# ATmega1281 device description
Architecture: AVR8; Family: megaAVR
Registers are 8-bit, access not given, no defined reset value unless marked. A register's access mark holds for its fields unless they carry their own. Offsets are from the block's base; [hi:lo] are bit positions; {n}, {i} and the like mark numbered series; 'fields as' and 'values as' point back to an identical list.

## EEPROM
Instances: EEPROM 0x00
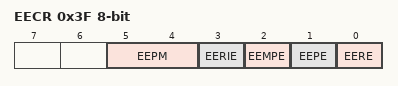
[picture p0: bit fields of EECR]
0x3F EECR — EEPROM Control Register
  [5:4] EEPM — EEPROM Programming Mode Bits
    0=ERASE_AND_WRITE_IN_ONE_OPERATION; 1=ERASE_ONLY; 2=WRITE_ONLY
  [3] EERIE — EEPROM Ready Interrupt Enable
  [2] EEMPE — EEPROM Master Write Enable
  [1] EEPE — EEPROM Write Enable
  [0] EERE — EEPROM Read Enable
0x40 EEDR — EEPROM Data Register
0x41 EEAR 16-bit bits used 11:0 — EEPROM Address Register Low Bytes

## JTAG — JTAG Interface
Instances: JTAG 0x00
0x51 OCDR — On-Chip Debug Related Register in I/O Memory
0x54 MCUSR — MCU Status Register
  [4] JTRF — JTAG Reset Flag
0x55 MCUCR — MCU Control Register
  [7] JTD — JTAG Interface Disable

## EXINT — External Interrupts
Instances: EXINT 0x00
0x3B PCIFR — Pin Change Interrupt Flag Register
  [2:0] PCIF — Pin Change Interrupt Flags
0x3C EIFR — External Interrupt Flag Register
  [7:0] INTF — External Interrupt Flags
0x3D EIMSK — External Interrupt Mask Register
  [7:0] INT — External Interrupt Request 7 Enable
0x68 PCICR — Pin Change Interrupt Control Register
  [2:0] PCIE — Pin Change Interrupt Enables
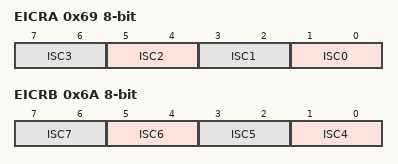
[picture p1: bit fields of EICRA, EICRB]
0x69 EICRA — External Interrupt Control Register A
  [all] fields
    0=LOW_LEVEL_OF_INTX; 1=ANY_LOGICAL_CHANGE_OF_INTX; 2=FALLING_EDGE_OF_INTX; 3=RISING_EDGE_OF_INTX
  [2n+1:2n] ISC{n} (n=0..3) — External Interrupt Sense Control Bit
0x6A EICRB — External Interrupt Control Register B
  [all] fields
    values as the fields of EICRA
  [2n-7:2n-8] ISC{n} (n=4..7) — External Interrupt 7-4 Sense Control Bit
0x6B PCMSK0 — Pin Change Mask Register 0
  [7:0] PCINT — Pin Change Enable mask
0x6C PCMSK1 — Pin Change Mask Register 1
  [7:0] PCINT (bit 8 of the value upward) — Pin Change Enable mask
0x6D PCMSK2 — Pin Change Mask Register 2
  [7:0] PCINT (bit 16 of the value upward) — Pin Change Enable mask

## ADC — Analog-to-Digital Converter
Instances: ADC 0x00
0x78 ADC 16-bit — ADC Data Register Bytes
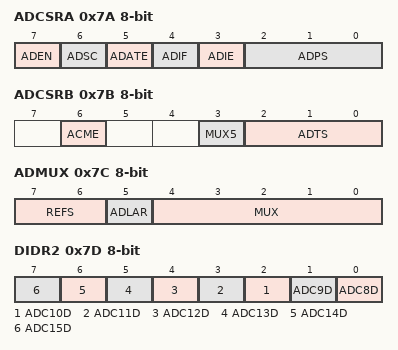
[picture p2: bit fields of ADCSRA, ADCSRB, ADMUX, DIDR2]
0x7A ADCSRA — The ADC Control and Status register A
  [7] ADEN — ADC Enable
  [6] ADSC — ADC Start Conversion
  [5] ADATE — ADC Auto Trigger Enable
  [4] ADIF — ADC Interrupt Flag
  [3] ADIE — ADC Interrupt Enable
  [2:0] ADPS — ADC Prescaler Select Bits
    0=2; 1=2; 2=4; 3=8; 4=16; 5=32; 6=64; 7=128
0x7B ADCSRB — The ADC Control and Status register B
  [6] ACME
  [3] MUX5 — Analog Channel and Gain Selection Bits
  [2:0] ADTS — ADC Auto Trigger Source bits
    0=FREE_RUNNING_MODE; 1=ANALOG_COMPARATOR; 2=EXTERNAL_INTERRUPT_REQUEST_0; 3=TIMER_COUNTER0_COMPARE_MATCH_A; 4=TIMER_COUNTER0_OVERFLOW; 5=TIMER_COUNTER1_COMPARE_MATCH_B; 6=TIMER_COUNTER1_OVERFLOW; 7=TIMER_COUNTER1_CAPTURE_EVENT
0x7C ADMUX — The ADC multiplexer Selection Register
  [7:6] REFS — Reference Selection Bits
    0=AREF_INTERNAL_VREF_TURNED_OFF; 1=AVCC_WITH_EXTERNAL_CAPACITOR_AT_AREF_PIN; 2=INTERNAL_1_1V_VOLTAGE_REFERENCE_WITH_EXTERNAL_CAPACITOR_AT_AREF_PIN; 3=INTERNAL_2_56V_VOLTAGE_REFERENCE_WITH_EXTERNAL_CAPACITOR_AT_AREF_PIN
  [5] ADLAR — Left Adjust Result
  [4:0] MUX — Analog Channel and Gain Selection Bits
    {v}=ADC{v} (ADC Single Ended Input pin {v}) (v=0..7); 8=ADC0_ADC0_10X (ADC Differential Inputs Positive pin 0 Negative pin 0 10x Gain); 9=ADC1_ADC0_10X (ADC Differential Inputs Positive pin 1 Negative pin 0 10x Gain); 10=ADC0_ADC0_200x (ADC Differential Inputs Positive pin 0 Negative pin 0 200x Gain); 11=ADC1_ADC0_200X (ADC Differential Inputs Positive pin 1 Negative pin 0 200x Gain); 12=ADC2_ADC2_10X (ADC Differential Inputs Positive pin 2 Negative pin 2 10x Gain); 13=ADC3_ADC2_10X (ADC Differential Inputs Positive pin 3 Negative pin 2 10x Gain); 14=ADC2_ADC2_200X (ADC Differential Inputs Positive pin 2 Negative pin 2 200x Gain); 15=ADC3_ADC2_200X (ADC Differential Inputs Positive pin 3 Negative pin 2 200x Gain); {v}=ADC{v-16}_ADC1_1X (ADC Differential Inputs Positive pin {v-16} Negative pin 1 1x Gain) (v=16..23); {v}=ADC{v-24}_ADC2_1X (ADC Differential Inputs Positive pin {v-24} Negative pin 2 1x Gain) (v=24..29); 30=ADC_VBG (Internal Reference (VBG)); 31=ADC_GND (0V (GND)); {v}=ADC{v-24} (ADC Single Ended Input pin {v-24}) (v=32..39); 40=ADC8_ADC8_10X (ADC Differential Inputs Positive pin 8 Negative pin 8 10x Gain); 41=ADC9_ADC8_10X (ADC Differential Inputs Positive pin 9 Negative pin 8 10x Gain); 42=ADC8_ADC8_200x (ADC Differential Inputs Positive pin 8 Negative pin 8 200x Gain); 43=ADC9_ADC8_200X (ADC Differential Inputs Positive pin 9 Negative pin 8 200x Gain); 44=ADC10_ADC10_10X (ADC Differential Inputs Positive pin 10 Negative pin 10 10x Gain); 45=ADC11_ADC10_10X (ADC Differential Inputs Positive pin 11 Negative pin 10 10x Gain); 46=ADC10_ADC10_200X (ADC Differential Inputs Positive pin 10 Negative pin 10 200x Gain); 47=ADC11_ADC10_200X (ADC Differential Inputs Positive pin 11 Negative pin 10 200x Gain); {v}=ADC{v-40}_ADC9_1X (ADC Differential Inputs Positive pin {v-40} Negative pin 9 1x Gain) (v=48..55); {v}=ADC{v-48}_ADC10_1X (ADC Differential Inputs Positive pin {v-48} Negative pin 10 1x Gain) (v=56..61)
0x7D DIDR2 — Digital Input Disable Register
  [n-8] ADC{n}D (n=8..15)
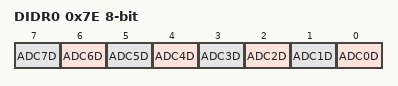
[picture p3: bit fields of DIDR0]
0x7E DIDR0 — Digital Input Disable Register
  [n] ADC{n}D (n=0..7)

## BOOT_LOAD — Bootloader
Instances: BOOT_LOAD 0x00
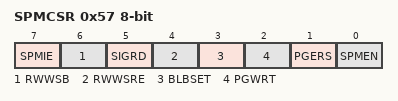
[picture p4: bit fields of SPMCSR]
0x57 SPMCSR — Store Program Memory Control Register
  [7] SPMIE — SPM Interrupt Enable
  [6] RWWSB — Read While Write Section Busy
  [5] SIGRD — Signature Row Read
  [4] RWWSRE — Read While Write section read enable
  [3] BLBSET — Boot Lock Bit Set
  [2] PGWRT — Page Write
  [1] PGERS — Page Erase
  [0] SPMEN — Store Program Memory Enable

## CPU — CPU Registers
Instances: CPU 0x00
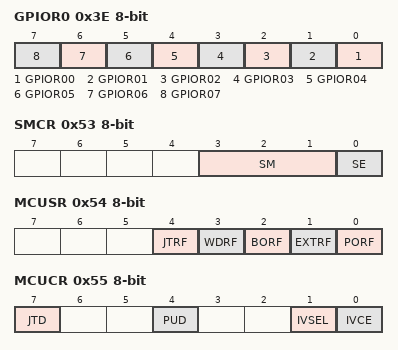
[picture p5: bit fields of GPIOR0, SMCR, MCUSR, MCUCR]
0x3E GPIOR0 — General Purpose IO Register 0
  [n] GPIOR{n:02} (n=0..7) — General Purpose IO Register 0 bit {n}
0x4A GPIOR1 — General Purpose IO Register 1
  [7:0] GPIOR (bit 10 of the value upward) — General Purpose IO Register 1 bis
0x4B GPIOR2 — General Purpose IO Register 2
  [7:0] GPIOR (bit 20 of the value upward) — General Purpose IO Register 2 bis
0x53 SMCR — Sleep Mode Control Register
  [3:1] SM — Sleep Mode Select bits
    0=IDLE; 1=ADC (ADC Noise Reduction (If Available)); 2=PDOWN (Power Down); 3=PSAVE (Power Save); 6=STDBY (Standby); 7=ESTDBY (Extended Standby)
  [0] SE — Sleep Enable
0x54 MCUSR — MCU Status Register
  [4] JTRF — JTAG Reset Flag
  [3] WDRF — Watchdog Reset Flag
  [2] BORF — Brown-out Reset Flag
  [1] EXTRF — External Reset Flag
  [0] PORF — Power-on reset flag
0x55 MCUCR — MCU Control Register
  [7] JTD — JTAG Interface Disable
  [4] PUD — Pull-up disable
  [1] IVSEL — Interrupt Vector Select
  [0] IVCE — Interrupt Vector Change Enable
0x5B RAMPZ bits used 1:0 — RAM Page Z Select Register
0x5D SP 16-bit — Stack Pointer
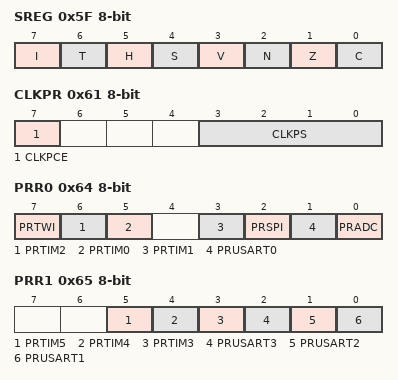
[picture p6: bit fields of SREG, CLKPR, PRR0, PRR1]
0x5F SREG — Status Register
  [7] I — Global Interrupt Enable
  [6] T — Bit Copy Storage
  [5] H — Half Carry Flag
  [4] S — Sign Bit
  [3] V — Two's Complement Overflow Flag
  [2] N — Negative Flag
  [1] Z — Zero Flag
  [0] C — Carry Flag
0x61 CLKPR
  [7] CLKPCE
  [3:0] CLKPS
    0=1; 1=2; 2=4; 3=8; 4=16; 5=32; 6=64; 7=128; 8=256
0x64 PRR0 — Power Reduction Register0
  [7] PRTWI — Power Reduction TWI
  [6] PRTIM2 — Power Reduction Timer/Counter2
  [5] PRTIM0 — Power Reduction Timer/Counter0
  [3] PRTIM1 — Power Reduction Timer/Counter1
  [2] PRSPI — Power Reduction Serial Peripheral Interface
  [1] PRUSART0 — Power Reduction USART0
  [0] PRADC — Power Reduction ADC
0x65 PRR1 — Power Reduction Register1
  [5] PRTIM5 — Power Reduction Timer/Counter5
  [4] PRTIM4 — Power Reduction Timer/Counter4
  [3] PRTIM3 — Power Reduction Timer/Counter3
  [2] PRUSART3 — Power Reduction USART3
  [1] PRUSART2 — Power Reduction USART2
  [0] PRUSART1 — Power Reduction USART1
0x66 OSCCAL — Oscillator Calibration Value
  [7:0] OSCCAL — Oscillator Calibration
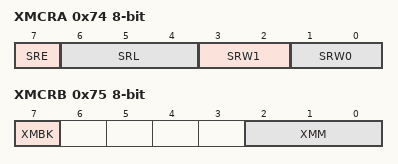
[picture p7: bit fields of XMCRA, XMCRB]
0x74 XMCRA — External Memory Control Register A
  [7] SRE — External SRAM Enable
  [6:4] SRL — Wait state page limit
    0=LS_N_A_US_0X1100_0XFFFF; 1=LS_0X2200_0X1FFF_US_0X2000_0XFFFF; 2=LS_0X2200_0X3FFF_US_0X4000_0XFFFF; 3=LS_0X2200_0X5FFF_US_0X6000_0XFFFF; 4=LS_0X2200_0X7FFF_US_0X8000_0XFFFF; 5=LS_0X2200_0X9FFF_US_0XA000_0XFFFF; 6=LS_0X2200_0XBFFF_US_0XC000_0XFFFF; 7=LS_0X2200_0XDFFF_US_0XE000_0XFFFF
  [3:2] SRW1 — Wait state select bit upper page
    0=NO_WAIT_STATES; 1=WAIT_ONE_CYCLE_DURING_READ_WRITE_STROBE; 2=WAIT_TWO_CYCLES_DURING_READ_WRITE_STROBE; 3=WAIT_TWO_CYCLES_DURING_READ_WRITE_AND_WAIT_ONE_CYCLE_BEFORE_DRIVING_OUT_NEW_ADDRESS
  [1:0] SRW0 — Wait state select bit lower page
    values as SRW1
0x75 XMCRB — External Memory Control Register B
  [7] XMBK — External Memory Bus Keeper Enable
  [2:0] XMM — External Memory High Mask
    0=NONE; 1=PX7; 2=PX7_PX6; 3=PX7_PX5; 4=PX7_PX4; 5=PX7_PX3; 6=PX7_PX2; 7=FULL_PORT_X
Value list OSCCAL_VALUE_ADDRESSES: 0=8_0_MHz
